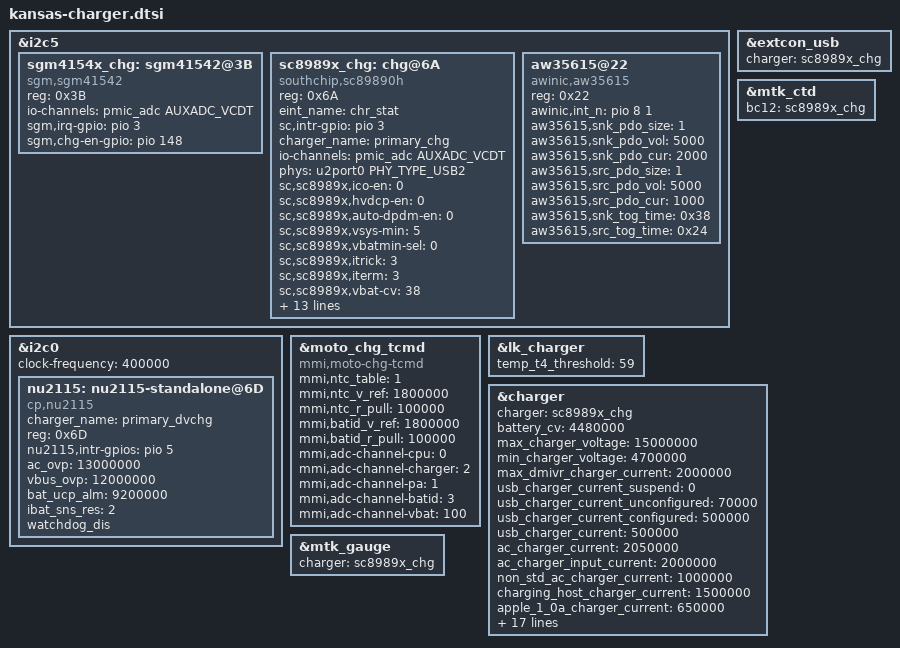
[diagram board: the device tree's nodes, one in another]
/*
 * Copyright (c) 2019 MediaTek Inc.
 *
 * This program is free software; you can redistribute it and/or modify
 * it under the terms of the GNU General Public License version 2 as
 * published by the Free Software Foundation.
 *
 * This program is distributed in the hope that it will be useful,
 * but WITHOUT ANY WARRANTY; without even the implied warranty of
 * MERCHANTABILITY or FITNESS FOR A PARTICULAR PURPOSE.  See the
 * GNU General Public License for more details.
 */
#include <dt-bindings/iio/mt635x-auxadc.h>
&i2c5 {
	sgm4154x_chg: sgm41542@3B {
		status = "okay";
		compatible = "sgm,sgm41542";
		reg = <0x3B>;
                io-channels = <&pmic_adc AUXADC_VCDT>;
		io-channel-names = "pmic_vbus";
		sgm,irq-gpio = <&pio 3 IRQ_TYPE_EDGE_FALLING>;     //irq num base on hardware design
		sgm,chg-en-gpio = <&pio 148 0>;   //gpio num base on hardware design  1.MTK parent node name is pio  2.QUALCOMM parent node name is tlmm or other
	};
	sc8989x_chg: chg@6A {
		compatible = "southchip,sc89890h";
		reg = <0x6A>;
		status = "okay";
		eint_name = "chr_stat";
		sc,intr-gpio = <&pio 3 IRQ_TYPE_EDGE_FALLING>;
		charger_name = "primary_chg";
		io-channels = <&pmic_adc AUXADC_VCDT>;
		io-channel-names = "pmic_vbus";
		phys = <&u2port0 PHY_TYPE_USB2>;
		phy-names = "usb2-phy";
		sc,sc8989x,ico-en = <0>;
		sc,sc8989x,hvdcp-en = <0>;
		sc,sc8989x,auto-dpdm-en = <0>;
		sc,sc8989x,vsys-min = <5>; /*3500mV*/
		sc,sc8989x,vbatmin-sel = <0>; /*0:2.9V 1:2.5V*/
		sc,sc8989x,itrick = <3>; /*60 + val *60*/
		sc,sc8989x,iterm = <3>; /*30 + val * 60*/
		sc,sc8989x,vbat-cv = <38>; /*3840 + val * 16*/
		sc,sc8989x,vbat-low = <1>; /*0:2.8V 1:3V*/
		sc,sc8989x,vrechg = <0>; /*0:100mV 1:200mV*/
		sc,sc8989x,en-term = <1>;
		sc,sc8989x,stat-dis = <0>;
		sc,sc8989x,wd-time = <0>; /*0:Dis 1:40s 2:80s 3:160s*/
		sc,sc8989x,en-timer = <1>;
		sc,sc8989x,charge-timer = <2>; /*0:5h 1:8h 2:12h 3:20h*/
		sc,sc8989x,bat-comp = <0>; /*val * 20*/
		sc,sc8989x,vclamp = <0>; /*val *32*/
		sc,sc8989x,votg = <12>; /*3900 + val * 100*/
		sc,sc8989x,iboost = <7>; /*0:0.5A 3:1.4A 5:1.875A 7:2.45A*/
		sc,sc8989x,force_vindpm = <0>;
		sc,sc8989x,vindpm = <18>; /*2600 + val * 100*/
	};
        aw35615@22 {
                compatible = "awinic,aw35615";
                reg = <0x22>;
                status = "okay";
                awinic,int_n = <&pio 8 1>;
                aw35615,snk_pdo_size = <1>; /* set sink pdo num*/
                aw35615,snk_pdo_vol = <5000>; /* set sink pdo voltage mV*/
                aw35615,snk_pdo_cur = <2000>; /* set sink pdo current mA*/
                aw35615,src_pdo_size = <1>; /* set source pdo num*/
                aw35615,src_pdo_vol = <5000>; /* set source pdo voltage mV*/
                aw35615,src_pdo_cur = <1000>; /* set source pdo current mA*/
                aw35615,snk_tog_time = <0x38>; /* set toggle sink time */
                aw35615,src_tog_time = <0x24>; /* set toggle source time */
        };
};

&i2c0 {
	clock-frequency = <400000>;
	nu2115: nu2115-standalone@6D {
		compatible = "cp,nu2115";
		status = "okay";
		charger_name = "primary_dvchg";
		reg = <0x6D>;
		nu2115,intr-gpios = <&pio 5 0x0>;
		ac_ovp = <13000000>;
		vbus_ovp = <12000000>;
		bat_ucp_alm = <9200000>;
		ibat_sns_res = <2>;
		watchdog_dis;
	};
};


&moto_chg_tcmd {
                compatible = "mmi,moto-chg-tcmd";
                status = "okay";

                mmi,ntc_table = <1>;
                mmi,ntc_v_ref = <1800000>;
                mmi,ntc_r_pull = <100000>;

                mmi,batid_v_ref = <1800000>;
                mmi,batid_r_pull = <100000>;

                mmi,adc-channel-cpu = <0>;
                mmi,adc-channel-charger = <2>;
                mmi,adc-channel-pa = <1>;
                mmi,adc-channel-batid = <3>;
                mmi,adc-channel-vbat = <100>;
};

&lk_charger {
        temp_t4_threshold = <59>;
};

&extcon_usb {
	charger = <&sc8989x_chg>;
};

&mtk_ctd {
	bc12 = <&sc8989x_chg>;
};
&charger {
	charger = <&sc8989x_chg>;
         /* common */
         battery_cv = <4480000>;
         max_charger_voltage = <15000000>;
         min_charger_voltage = <4700000>;
         max_dmivr_charger_current = <2000000>;

         //enable_pe_plus;
         //enable_sw_jeita;

         /* charging current */
         usb_charger_current_suspend = <0>;
         usb_charger_current_unconfigured = <70000>;
         usb_charger_current_configured = <500000>;
         usb_charger_current = <500000>;
         ac_charger_current = <2050000>;
         ac_charger_input_current = <2000000>;
         non_std_ac_charger_current = <1000000>;
         charging_host_charger_current = <1500000>;
         apple_1_0a_charger_current = <650000>;
         apple_2_1a_charger_current = <800000>;
         ta_ac_charger_current = <3600000>;
         typec_limit_aicr = <3000000>;

         /* PE */
         ta_ac_9v_input_current = <2000000>;
         ta_ac_7v_input_current = <2000000>;

         //mmi config
         mmi,iterm-ma = <243>;
         mmi,mmi-temp-zones =
                        <0 4200 1000  0>,
                        <10 4250 3000 1000>,
                        <15 0 3000 3000>,
                        <25 0 3776 3776>,
                        <35 0 3776 3776>,
                        <45 0 3776 3776>,
                        <60 4200 3776 0>;

	mmi,mmi-ffc-zones =
                         <4200 243>,
                         <4480 243>,
                         <4480 243>,
                         <4510 518>,
                         <4510 536>,
                         <4510 548>,
                         <4200 243>;

         mmi,enable-charging-limit;
         mmi,upper-limit-capacity = <65>;
         mmi,lower-limit-capacity = <60>;
         mmi,vfloat-comp-uv = <0>;
};

&mtk_gauge {
	charger = <&sc8989x_chg>;
};
